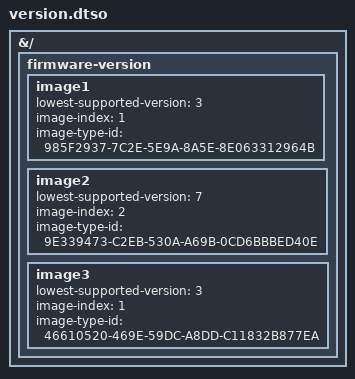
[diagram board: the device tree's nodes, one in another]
// SPDX-License-Identifier: GPL-2.0+

/dts-v1/;
/plugin/;

&{/} {
	firmware-version {
		image1 {
			lowest-supported-version = <3>;
			image-index = <1>;
			image-type-id = "985F2937-7C2E-5E9A-8A5E-8E063312964B";
		};
		image2 {
			lowest-supported-version = <7>;
			image-index = <2>;
			image-type-id = "9E339473-C2EB-530A-A69B-0CD6BBBED40E";
		};
		image3 {
			lowest-supported-version = <3>;
			image-index = <1>;
			image-type-id = "46610520-469E-59DC-A8DD-C11832B877EA";
		};
	};
};
